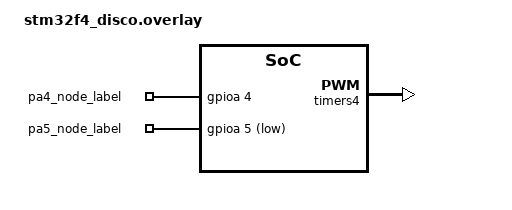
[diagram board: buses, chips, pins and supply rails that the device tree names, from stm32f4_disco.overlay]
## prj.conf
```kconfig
CONFIG_GPIO=y

CONFIG_TRACING=y
CONFIG_SEGGER_SYSTEMVIEW=y
```

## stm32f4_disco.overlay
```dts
/ {
    gpio_pins { 
        compatible = "gpio-keys";
        pa4_node_label: pa4 {
            gpios = <&gpioa 4 GPIO_ACTIVE_HIGH>;
        };
        pa5_node_label: pa5 {
            gpios = <&gpioa 5 GPIO_ACTIVE_LOW>;
        };
    };
};

timer4: &timers4 {
    status = "okay";
    st,prescaler = <8400>;

    pmw4: pwm {
        status = "okay";
        pinctrl-0 = <&tim4_ch1_pb6>;
        pinctrl-names = "default";
    };
};
```

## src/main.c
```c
/*
 * Copyright (c) 2016 Intel Corporation
 *
 * SPDX-License-Identifier: Apache-2.0
 */

#include <zephyr/kernel.h>
#include <zephyr/drivers/gpio.h>


#define ORANGE_LED_NODE DT_NODELABEL(orange_led_3)

const struct gpio_dt_spec orange_led_spec = GPIO_DT_SPEC_GET(ORANGE_LED_NODE, gpios);

void main(void){ 
    gpio_pin_configure_dt(&orange_led_spec, GPIO_OUTPUT_LOW);
    while(1){
        gpio_pin_toggle_dt(&orange_led_spec);
        k_msleep(500);
    }
}
```
